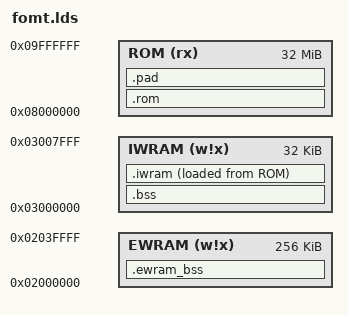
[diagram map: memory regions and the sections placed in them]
OUTPUT_ARCH(arm)

_M4aNumMusicPlayers = 5;
_M4aMaxLines = 0x50;

gMPlayJumpTableTemplate = 0x08139A88;
gScaleTable = 0x08139B18;
gFreqTable = 0x08139BCC;
gPcmSamplesPerVBlankTable = 0x08139BFC;
gCgbScaleTable = 0x08139C14;
gCgbFreqTable = 0x08139C98;
gNoiseTable = 0x08139CB0;
gCgb3Vol = 0x08139CEC;
gClockTable = 0x08139CFC;
gXcmdTable = 0x08139D30;

MEMORY
{
    EWRAM (w!x) : ORIGIN = 0x02000000, LENGTH = 256K
    IWRAM (w!x) : ORIGIN = 0x03000000, LENGTH = 32K
    ROM   (rx)  : ORIGIN = 0x08000000, LENGTH = 32M
}

SECTIONS
{
    .ewram_bss (NOLOAD) : ALIGN(4)
    {
        . = ALIGN(4); src/sound_data.o(.sbss);
        . = ALIGN(4); src/m4a.o(.gSoundInfo);
        . = ALIGN(4); src/m4a.o(.gMPlayJumpTable);
        . = ALIGN(4); src/m4a.o(.gCgbChans);
        . = ALIGN(4); src/m4a.o(.gMusicPlayerA);
        . = ALIGN(4); src/m4a.o(.gMusicPlayerB);
        . = ALIGN(4); src/m4a.o(.gMusicPlayerC);
        . = ALIGN(4); src/m4a.o(.gMusicPlayerE);
        . = ALIGN(4); src/m4a.o(.gMPlayMemAccArea);
        . = ALIGN(4); src/m4a.o(.gMusicPlayerD);
        __ewram_bss_end = .;
    } > EWRAM

    .bss (NOLOAD) : ALIGN(4)
    {
        . = ALIGN(4); src/m4a.o(.bss);
        . = ALIGN(4);
        . = 0x000400; gUnk_03000400 = .;
        . = 0x000402; gUnk_03000402 = .;
        . = 0x000404; gUnk_03000404 = .;
        . = 0x000408; gUnk_03000408 = .;
        . = 0x00040C; gUnk_0300040C = .;
        . = 0x000410; gUnk_03000410 = .;
        . = 0x000414; gUnk_03000414 = .;
        . = 0x000418; gUnk_03000418 = .;
        . = 0x00041C; gUnk_0300041C = .;
        . = 0x000420; gUnk_03000420 = .;
        . = 0x000430; gUnk_03000430 = .;
        . = 0x000450; gUnk_03000450 = .;
        . = 0x000490; /* end */
    } > IWRAM

    .rom : ALIGN(4)
    {
        src/crt0.o(.rom_header);
        asm/main.o(.text);
        asm/sram_proxy_1.o(.text);
        src/code_080003DC.o(.text);
        asm/sram_proxy_1.o(.text.tail080003E8);
        src/code_080004C4.o(.text);
        src/code_080004F4.o(.text);
        src/code_0800050C.o(.text);
        src/code_08000528.o(.text);
        src/code_08000540.o(.text);
        src/code_08000554.o(.text);
        src/code_08000568.o(.text);
        src/code_0800057C.o(.text);
        src/new.o(.text);
        src/pure_virtual.o(.text);
        src/code_0800063C.o(.text);
        src/code_08000640.o(.text);
        asm/sram_proxy_2_prefix.o(.text);
        src/code_080006A4.o(.text);
        src/code_080006E4.o(.text);
        src/code_08000714.o(.text);
        asm/sram_proxy_2.o(.text);
        src/scene.o(.text);
        asm/scene.o(.text);
        asm/intro_scene.o(.text);
        src/code_080036F8.o(.text);
        src/code_0800371C.o(.text);
        src/code_0800374C.o(.text);
        asm/new_game.o(.text);
        src/code_08004B58.o(.text);
        src/code_08004B94.o(.text);
        src/code_08004BDC.o(.text);
        src/code_08004C0C.o(.text);
        src/code_08004C48.o(.text);
        src/code_08004C54.o(.text);
        asm/code_08004C68.o(.text);
        src/code_08005254.o(.text);
        src/code_08005260.o(.text);
        asm/code_08004C68.o(.text.tail08005278);
        src/code_0800598C.o(.text);
        src/code_080059D0.o(.text);
        src/code_08005A00.o(.text);
        src/code_08005A3C.o(.text);
        asm/code_08005A58.o(.text);
        src/code_08007078.o(.text);
        src/code_080070A4.o(.text);
        src/code_080070D4.o(.text);
        src/code_08007110.o(.text);
        src/code_0800711C.o(.text);
        src/hardware.o(.text);
        src/code_080074C0.o(.text);
        asm/code_08007510.o(.text);
        src/code_0800770C.o(.text);
        asm/code_08007510.o(.text.tail08007714);
        src/code_08007D4C.o(.text);
        src/code_08007DB8.o(.text);
        src/code_08007E24.o(.text);
        src/code_08007E8C.o(.text);
        src/code_08007EA0.o(.text);
        src/code_08007EA8.o(.text);
        src/code_08007EC8.o(.text);
        asm/code_08007DB8.o(.text);
        src/code_0800835C.o(.text);
        asm/code_08007DB8.o(.text.tail08008364);
        src/code_080088B8.o(.text);
        src/code_080088C4.o(.text);
        src/code_080088CC.o(.text);
        src/code_080088D4.o(.text);
        src/code_080088DC.o(.text);
        src/code_08008910.o(.text);
        src/code_08008918.o(.text);
        src/code_08008920.o(.text);
        src/code_08008928.o(.text);
        src/code_08008940.o(.text);
        src/code_08008960.o(.text);
        src/code_08008980.o(.text);
        src/code_08008A68.o(.text);
        src/code_08008AE0.o(.text);
        src/code_08008AE8.o(.text);
        src/code_08008AF0.o(.text);
        src/code_08008AFC.o(.text);
        src/code_08008B0C.o(.text);
        src/code_08008B18.o(.text);
        src/code_08008B24.o(.text);
        src/code_08008B54.o(.text);
        src/code_08008B6C.o(.text);
        src/code_08008BB0.o(.text);
        src/code_08008BE0.o(.text);
        src/code_08008BEC.o(.text);
        src/code_08008BF8.o(.text);
        src/code_08008C08.o(.text);
        src/code_08008C28.o(.text);
        src/code_08008C38.o(.text);
        src/code_08008C54.o(.text);
        src/code_08008C70.o(.text);
        src/code_08008C8C.o(.text);
        src/code_08008CA8.o(.text);
        src/code_08008CC4.o(.text);
        src/code_08008CD0.o(.text);
        src/code_08008CDC.o(.text);
        asm/code_08008D10.o(.text);
        src/code_08008D2C.o(.text);
        src/code_08008D3C.o(.text);
        src/code_08008D5C.o(.text);
        src/code_08008D84.o(.text);
        src/code_08008D90.o(.text);
        src/code_08008D9C.o(.text);
        src/code_08008DA8.o(.text);
        src/code_08008DB8.o(.text);
        asm/code_08008DE8_prefix.o(.text);
        src/code_08008DE8.o(.text);
        src/code_08008DF4.o(.text);
        src/code_08008E04.o(.text);
        asm/code_08008E64_prefix.o(.text);
        src/code_08008E64.o(.text);
        src/code_08008EB8.o(.text);
        src/code_08008F0C.o(.text);
        asm/code_08008F60.o(.text);
        src/code_0800912C.o(.text);
        asm/code_08008F60.o(.text.tail08009140);
		src/code_08009158.o(.text.func_08009140);
        src/code_08009154.o(.text);
        asm/code_08008F60.o(.text.tail08009158);
		src/code_08009158.o(.text);
		asm/code_08008F60.o(.text.tail080091A4);
        src/code_080092FC.o(.text);
        asm/code_08008F60.o(.text.tail08009300);
        src/code_08009344.o(.text);
        asm/code_08008F60.o(.text.tail0800934C);
		src/code_simple_short.o(.text.func_080093A0);
		asm/code_08008F60.o(.text.tail080093AC);
        src/code_080094A4.o(.text);
        asm/code_08008F60.o(.text.tail080094AC);
        src/code_080094AC.o(.text);
        src/code_080094B8.o(.text);
        src/code_080094E0.o(.text);
        asm/code_0800956C_prefix.o(.text);
        src/code_0800956C.o(.text);
        src/code_0800959C.o(.text);
        src/code_080095C0.o(.text);
        src/code_080095FC.o(.text);
        src/code_08009638.o(.text);
        src/code_08009674.o(.text);
        asm/code_0800956C.o(.text);
        src/code_0800977C.o(.text);
        src/code_08009790.o(.text);
        asm/code_080097A4.o(.text);
        src/code_08009834.o(.text);
        src/code_08009864.o(.text);
        src/code_08009878.o(.text);
        src/code_080098AC.o(.text);
        asm/code_080098AC.o(.text);
        src/code_080098DC.o(.text);
        src/code_08009908.o(.text);
        src/code_08009940.o(.text);
        src/code_08009968.o(.text);
        src/code_08009984.o(.text);
        src/code_080099B0.o(.text);
        src/code_080099D4.o(.text);
        src/code_080099EC.o(.text);
        src/farm.o(.text);
        src/field.o(.text);
        src/shipping_bin.o(.text);
        src/tool_chest.o(.text);
        src/fridge.o(.text);
        src/shelf.o(.text);
        src/record_player.o(.text);
        src/code_0800BC58.o(.text);
        src/farm_house.o(.text);
        src/coop.o(.text);
        src/barn.o(.text);
        src/item.o(.text);
        src/code_0800E2E4.o(.text);
        src/farmer.o(.text);
        src/rucksack_item.o(.text);
        src/held_item.o(.text);
        src/rucksack.o(.text);
        asm/more_items.o(.text);
        src/code_0800FFD0.o(.text);
        src/code_0800FFD4.o(.text);
        src/code_0800FFD8.o(.text);
        src/code_0800FFE0.o(.text);
        src/code_0800FFF4.o(.text);
        src/code_08010014.o(.text);
        asm/more_items_tail.o(.text);
        asm/game_scene.o(.text);
        src/code_080100F0.o(.text);
        src/code_08010158.o(.text);
        asm/code_080101A0.o(.text);
        src/code_08010348.o(.text);
        asm/game_state.o(.text);
        src/code_08010E48.o(.text);
        asm/game_state.o(.text.tail08010E68);
        src/code_08010F04.o(.text);
        src/code_08010F0C.o(.text);
        src/code_08010F14.o(.text);
        src/game_state.o(.text);
        asm/code_08010F54.o(.text);
        src/code_08011458.o(.text);
		asm/code_08010F54.o(.text.tail08011464);
		src/code_simple_short.o(.text.func_08011510);
        src/code_0801151C.o(.text);
        asm/code_08010F54.o(.text.tail08011524);
        src/code_08011540.o(.text);
        asm/code_08010F54.o(.text.tail08011544);
        src/code_08011544.o(.text);
        asm/code_08010F54.o(.text.tail08011550);
        src/code_08011ED8.o(.text);
        src/code_08011FE8.o(.text);
        asm/code_08012028.o(.text);
        src/code_08012218.o(.text);
        asm/code_08012028.o(.text.tail0801221C);
		src/code_08012454.o(.text.func_08012454);
		asm/code_08012028.o(.text.tail08012464);
        src/code_080124C4.o(.text);
        asm/code_08012028.o(.text.tail080124D0);
		src/code_0801274C.o(.text.func_0801274C);
		asm/code_08012028.o(.text.tail08012760);
		src/code_0801274C.o(.text.func_0801278C);
		asm/code_08012028.o(.text.tail080127A0);
		src/code_0801274C.o(.text.func_0801284C);
		asm/code_08012028.o(.text.tail08012860);
		src/code_08012454.o(.text.func_08012ACC);
		asm/code_08012028.o(.text.tail08012ADC);
		src/code_08012454.o(.text.func_08012BAC);
		asm/code_08012028.o(.text.tail08012BBC);
		src/code_08012454.o(.text.func_080142F0);
		src/code_08012454.o(.text.func_08014304);
		asm/code_08012028.o(.text.tail08014318);
        src/code_0801468C.o(.text);
        asm/code_08012028.o(.text.tail08014694);
		src/code_08012454.o(.text.func_080167CC);
		asm/code_08012028.o(.text.tail080167DC);
		src/code_simple_short.o(.text.func_08016D9C);
		asm/code_08012028.o(.text.tail08016DB0);
        src/code_0801DD18.o(.text);
        src/code_0801DD24.o(.text);
        src/code_0801DD30.o(.text);
src/code_0801DD3C.o(.text);
        src/code_0801DD78.o(.text);
asm/code_0801DD78.o(.text);
        src/code_0801DDCC.o(.text);
        src/code_0801DDF8.o(.text);
        src/code_0801DE24.o(.text);
        src/code_0801DE30.o(.text);
        src/code_0801DE3C.o(.text);
        src/code_0801DE48.o(.text);
        asm/code_0801DE3C.o(.text);
		src/code_0801FAA8.o(.text);
		asm/code_0801DE3C.o(.text.tail0801FAC8);
        src/code_0801FD3C.o(.text);
        src/code_0801FD48.o(.text);
        src/code_0801FD60.o(.text);
        src/entity.o(.text);
        src/code_entity_08020018.o(.text);
        src/code_08020060.o(.text);
        asm/code_entities.o(.text);
        src/code_080202C4.o(.text);
        asm/code_entities.o(.text.tail080202CC);
		src/code_08020460.o(.text);
		asm/code_entities.o(.text.tail08020474);
        src/code_0802161C.o(.text);
		src/code_short_mappers.o(.text.func_08021620);
		asm/code_entities.o(.text.tail08021634);
        src/code_080222A8.o(.text);
        asm/code_08022320_prefix.o(.text);
        src/code_08022320.o(.text);
        src/code_08022334.o(.text);
        asm/code_08022320.o(.text);
		src/code_08037628.o(.text.func_080229A4);
		asm/code_08022320.o(.text.tail080229B8);
        src/code_08022B58.o(.text);
		src/code_short_mappers.o(.text.func_08022B5C);
		asm/code_08022320.o(.text.tail08022B70);
		src/code_08037628.o(.text.func_08023400);
		asm/code_08022320.o(.text.tail08023414);
		src/code_short_mappers.o(.text.func_080237F0);
		src/code_short_mappers.o(.text.func_08023804);
		asm/code_08022320.o(.text.tail08023820);
		src/code_08037628.o(.text.func_080240BC);
		asm/code_08022320.o(.text.tail080240D0);
		src/code_short_mappers.o(.text.func_080244C4);
		src/code_short_mappers.o(.text.func_080244D8);
		asm/code_08022320.o(.text.tail080244EC);
		src/code_08024BE8.o(.text);
		asm/code_08022320.o(.text.tail08024BFC);
		src/code_08024C54.o(.text);
		asm/code_08022320.o(.text.tail08024C74);
		src/code_08024C54.o(.text.func_08024C88);
        src/code_08024C98.o(.text);
        asm/code_08022320.o(.text.tail08024CA0);
		src/code_08025AFC.o(.text);
        asm/code_08022320.o(.text.tail08025B10);
        src/code_0802A7D8.o(.text);
        asm/code_08022320.o(.text.tail0802A7E0);
		src/code_0802C210.o(.text);
		asm/code_08022320.o(.text.tail0802C228);
        src/code_0802C2DC.o(.text);
        asm/code_08022320.o(.text.tail0802C2E0);
        src/entity_actor.o(.text);
        asm/code_entities_080320DC.o(.text);
        src/code_080324B8.o(.text);
        asm/code_entities_080320DC.o(.text.tail080324BC);
        src/code_08032A00.o(.text);
        asm/code_08032A30.o(.text);
		src/code_08033914.o(.text);
		asm/code_08032A30.o(.text.tail08033928);
        src/code_08033B7C.o(.text);
        asm/code_08032A30.o(.text.tail08033B84);
        src/npc_entity.o(.text);
        asm/code_entities_08034CEC.o(.text);
        src/code_08035B38.o(.text);
        src/code_08035B64.o(.text);
        src/code_08035B9C.o(.text);
        src/code_08035BC8.o(.text);
        asm/code_08035BC8.o(.text);
        src/code_08035CB8.o(.text);
        src/code_08035CD4.o(.text);
        src/code_08035D04.o(.text);
        src/code_08035D40.o(.text);
        src/code_08035D70.o(.text);
        src/code_08035DAC.o(.text);
        src/code_08035DD8.o(.text);
        src/code_08035E14.o(.text);
        src/code_08035E40.o(.text);
        src/code_08035E7C.o(.text);
        src/code_08035EAC.o(.text);
        src/code_08035EE4.o(.text);
        src/code_08035F10.o(.text);
        src/code_08035F48.o(.text);
        src/code_08035F74.o(.text);
        src/code_08035FB0.o(.text);
        src/code_08035FE0.o(.text);
        src/code_0803601C.o(.text);
        src/code_08036048.o(.text);
        asm/code_08036048.o(.text);
        src/code_08036138.o(.text);
        src/code_08036154.o(.text);
        src/code_08036184.o(.text);
        src/code_080361C0.o(.text);
        src/code_080361EC.o(.text);
        src/code_08036228.o(.text);
        src/code_08036258.o(.text);
        src/code_08036290.o(.text);
        src/code_080362C0.o(.text);
        src/code_080362FC.o(.text);
        src/code_08036328.o(.text);
        src/code_08036364.o(.text);
        src/code_08036390.o(.text);
        src/code_080363CC.o(.text);
        src/code_080363F8.o(.text);
        asm/code_080363F8.o(.text);
        src/code_080364E4.o(.text);
        src/code_08036500.o(.text);
        src/code_08036530.o(.text);
        src/code_08036564.o(.text);
        src/code_08036590.o(.text);
        asm/code_08036590.o(.text);
        src/code_08036680.o(.text);
        src/code_0803669C.o(.text);
        src/code_080366CC.o(.text);
        src/code_08036704.o(.text);
        src/code_08036730.o(.text);
        src/code_08036768.o(.text);
        src/code_080367AC.o(.text);
        src/code_080367C8.o(.text);
        src/code_080367F8.o(.text);
        src/code_08036834.o(.text);
        src/code_08036860.o(.text);
        src/code_08036898.o(.text);
        src/code_080368C4.o(.text);
        asm/code_080368C4.o(.text);
        src/code_080369C4.o(.text);
        src/code_080369E0.o(.text);
        src/code_08036A10.o(.text);
        src/code_08036A4C.o(.text);
        src/code_08036A78.o(.text);
        src/code_08036AB4.o(.text);
        src/code_08036B00.o(.text);
        src/code_08036B1C.o(.text);
        src/code_08036B4C.o(.text);
        src/code_08036B80.o(.text);
        asm/code_08036BB0.o(.text);
        src/code_08036C48.o(.text);
        src/code_08036C80.o(.text);
        src/code_08036CAC.o(.text);
        src/code_08036CDC.o(.text);
        src/code_08036D0C.o(.text);
        src/code_08036D3C.o(.text);
        src/code_08036D68.o(.text);
        src/code_08036D98.o(.text);
        src/code_08036DC4.o(.text);
        src/code_08036E00.o(.text);
        src/code_08036E2C.o(.text);
        asm/code_08036E2C.o(.text);
        src/code_08037244.o(.text);
        asm/code_08036E2C.o(.text.tail08037250);
        src/code_08037430.o(.text);
        asm/code_08036E2C.o(.text.tail08037434);
		src/code_0803745C.o(.text);
		asm/code_08036E2C.o(.text.tail08037470);
        src/code_0803753C.o(.text);
        asm/code_08037568.o(.text);
        src/code_08037618.o(.text);
		src/code_08037628.o(.text.func_08037628);
		asm/code_08037568.o(.text.tail0803763C);
        src/code_080376E4.o(.text);
        asm/code_08037714.o(.text);
        src/code_080377C4.o(.text);
		src/code_08037628.o(.text.func_080377D4);
		asm/code_08037714.o(.text.tail080377E8);
        src/code_0803788C.o(.text);
        src/code_080378B8.o(.text);
        src/code_080378EC.o(.text);
        src/code_080378FC.o(.text);
        asm/code_080378B8.o(.text);
        src/code_080379D8.o(.text);
        src/code_08037A04.o(.text);
        src/code_08037A38.o(.text);
        src/code_08037A48.o(.text);
        asm/code_08037A04.o(.text);
		src/code_08037CC4.o(.text);
		asm/code_08037A04.o(.text.tail08037CDC);
		src/code_allocator_wrappers.o(.text.func_08037CF0);
		asm/code_08037A04.o(.text.tail08037D08);
		src/code_allocator_wrappers.o(.text.func_08037E9C);
		asm/code_08037A04.o(.text.tail08037EB4);
        src/code_08037F74.o(.text);
        asm/code_08037A04.o(.text.tail08037F7C);
        src/code_08038108.o(.text);
        asm/code_08037A04.o(.text.tail08038110);
		src/code_08038320.o(.text);
		asm/code_08037A04.o(.text.tail08038334);
		src/code_allocator_wrappers.o(.text.func_08038334);
		asm/code_08037A04.o(.text.tail0803834C);
        src/code_0803836C.o(.text);
        asm/code_08037A04.o(.text.tail08038374);
		src/code_080387B8.o(.text.func_080387B8);
		src/code_080387B8.o(.text.func_080387C8);
		asm/code_08037A04.o(.text.tail080387D8);
		src/code_080387B8.o(.text.func_080387EC);
		src/code_080387B8.o(.text.func_080387FC);
		asm/code_08037A04.o(.text.tail0803880C);
		src/code_080387B8.o(.text.func_08038E90);
		asm/code_08037A04.o(.text.tail08038EA0);
        src/code_080390D0.o(.text);
        asm/code_08037A04.o(.text.tail080390DC);
        src/code_080391FC.o(.text);
        asm/code_08037A04.o(.text.tail08039204);
        src/code_0803930C.o(.text);
        asm/code_08037A04.o(.text.tail08039310);
		src/code_080396F4.o(.text);
		asm/code_08037A04.o(.text.tail08039708);
        src/code_08039A30.o(.text);
        src/code_08039A5C.o(.text);
        asm/code_08039A5C.o(.text);
        src/code_08039D4C.o(.text);
        asm/code_08039A5C.o(.text.tail08039D5C);
		src/code_08039D98.o(.text);
		asm/code_08039A5C.o(.text.tail08039DA8);
        src/code_0803A798.o(.text);
        src/code_0803A804.o(.text);

        asm/code_0803A8A4.o(.text);
        src/code_0803BDE4.o(.text);
        src/code_0803BDEC.o(.text);
        asm/code_0803A8A4.o(.text.tail0803BDEC);
        asm/code_0803A8A4.o(.text.tail0803BDFC);
        src/code_0803BE9C.o(.text);
        src/code_0803BEB0.o(.text);
        src/code_0803BEBC.o(.text);
        src/code_0803BEC8.o(.text);
        src/code_0803BED4.o(.text);
        src/code_0803BEE0.o(.text);
        src/code_0803BEEC.o(.text);
        src/code_0803BEF4.o(.text);
        src/code_0803BEFC.o(.text);
        src/code_0803BF08.o(.text);
        src/code_0803BF14.o(.text);
        src/code_0803BF78.o(.text);
        src/code_0803BFC8.o(.text);
        asm/code_0803BFC8_prefix.o(.text);
        src/code_0803C00C.o(.text);
        asm/code_0803D644_prefix.o(.text);
		src/code_0803C518.o(.text);
        src/code_0803C540.o(.text);
        src/code_0803C544.o(.text);
        asm/code_0803D644_prefix.o(.text.tail0803C54C);
        src/code_0803D644.o(.text);
        asm/code_0803BFC8.o(.text);
        src/script_engine.o(.text);
        asm/code_0803EE94.o(.text);
        src/code_0804E4AC.o(.text);
        src/code_0804E5AC.o(.text);
        src/code_0804E7A0.o(.text);
        asm/code_0804E7A0.o(.text);
        src/code_0804E8F0.o(.text);
        src/code_0804E958.o(.text);
        src/code_0804E9C8.o(.text);
        src/code_0804E9CC.o(.text);
        asm/code_0804E9C8.o(.text);
		src/code_0804EA80.o(.text.func_0804EA80);
		asm/code_0804E9C8.o(.text.tail0804EA94);
		src/code_0804EA80.o(.text.func_0804EDA0);
		asm/code_0804E9C8.o(.text.tail0804EDB4);
		src/code_0804EA80.o(.text.func_0804EE1C);
		asm/code_0804E9C8.o(.text.tail0804EE30);
		src/code_0804EA80.o(.text.func_0804EE88);
		asm/code_0804E9C8.o(.text.tail0804EE9C);
        src/code_0804F15C.o(.text);
		src/code_0804F160.o(.text);
        src/code_0804F174.o(.text);
        asm/code_0804E9C8.o(.text.tail0804F178);
		src/code_080503E4.o(.text);
		asm/code_0804E9C8.o(.text.tail08050424);
        src/code_080507D0.o(.text);
        asm/code_080507F8.o(.text);
        src/code_08050868.o(.text);
        asm/code_08050AD8.o(.text);
		src/code_08050B3C.o(.text.func_08050B3C);
		asm/code_08050AD8.o(.text.tail08050B50);
		src/code_08050B3C.o(.text.func_08050C18);
		asm/code_08050AD8.o(.text.tail08050C2C);
		src/code_08050C64.o(.text);
		asm/code_08050AD8.o(.text.tail08050C70);
        src/code_08050D0C.o(.text);
        src/code_08050D34.o(.text);
        src/code_08050D3C.o(.text);
        src/code_08050D5C.o(.text);
        src/code_08050D68.o(.text);
        src/code_08050D74.o(.text);
        src/code_08050D80.o(.text);
        src/code_08050D8C.o(.text);
        src/code_08050DA0.o(.text);
        src/code_08050DB4.o(.text);
        src/code_08050DC8.o(.text);
        src/code_08050DD8.o(.text);
        src/code_08050DE4.o(.text);
        src/code_08050DF0.o(.text);
        src/code_08050E0C.o(.text);
        src/code_08050E30.o(.text);
        src/code_08050E50.o(.text);
        src/code_08050E5C.o(.text);
        src/code_08050E68.o(.text);
        src/code_08050E74.o(.text);
        src/code_08050E80.o(.text);
        src/code_08050E8C.o(.text);
        src/code_08050E98.o(.text);
        src/code_08050EBC.o(.text);
        src/code_08050EE4.o(.text);
        asm/code_08050F4C.o(.text);
        src/code_08050F60.o(.text);
        src/code_08050F70.o(.text);
        src/code_08050F74.o(.text);
        asm/code_08050FA0.o(.text);
        src/code_080512B8.o(.text);
        src/code_080512C8.o(.text);
        src/code_080512D0.o(.text);
        src/code_080512D8.o(.text);
        asm/code_08051320.o(.text);
        src/code_0805218C.o(.text);
        src/code_080521BC.o(.text);
        src/code_080521FC.o(.text);
        asm/code_080521FC.o(.text);
		src/code_simple_short.o(.text.func_080522D8);
		src/code_simple_short.o(.text.func_080522E8);
		asm/code_080521FC.o(.text.tail080522F8);
        src/code_08057DD8.o(.text);
        src/code_08057E1C.o(.text);
        src/code_08057E5C.o(.text);
        asm/code_08057E5C.o(.text);
        src/code_0805CEB8.o(.text);
        src/code_0805CEFC.o(.text);
        src/code_0805CF3C.o(.text);
        asm/code_0805CF3C.o(.text);
        src/code_0805E624.o(.text);
        src/code_0805E658.o(.text);
        src/code_0805E698.o(.text);
        src/code_0805E6CC.o(.text);
        asm/code_0805E760.o(.text);
        src/code_0805E850.o(.text);
        src/code_0805E860.o(.text);
        asm/code_0805E860.o(.text);
        src/code_0805E8F0.o(.text);
        asm/code_0805E99C.o(.text);
        src/code_0805EC24.o(.text);
        asm/code_0805ED4C.o(.text);
        src/code_0805FCD0.o(.text);
        src/code_0805FD04.o(.text);
        src/code_0805FD44.o(.text);
        asm/code_0805FD44.o(.text);
		src/code_08063E58.o(.text);
		asm/code_0805FD44.o(.text.tail08063E64);
        src/code_08069E14.o(.text);
        src/code_08069E58.o(.text);
        src/code_08069E98.o(.text);
        src/code_08069EB4.o(.text);
        asm/code_08069F14.o(.text);
        src/code_0806D8C8.o(.text);
        src/code_0806D918.o(.text);
        src/code_0806D948.o(.text);
        src/code_0806D984.o(.text);
        asm/code_0806D948.o(.text);
        src/code_0806E9D8.o(.text);
        src/code_0806EA00.o(.text);
        src/code_0806EA30.o(.text);
        src/code_0806EA6C.o(.text);
        asm/code_0806EA78.o(.text);
        src/code_080709D8.o(.text);
        asm/code_08070A08.o(.text);
		src/code_vtable_tail_wrappers.o(.text.func_08070C88);
		asm/code_08070A08.o(.text.tail08070CA4);
		src/code_080713AC.o(.text.func_080713AC);
		asm/code_08070A08.o(.text.tail080713B8);
		src/code_080713AC.o(.text.func_080722D0);
		asm/code_08070A08.o(.text.tail080722DC);
		src/code_080713AC.o(.text.func_08075328);
		asm/code_08070A08.o(.text.tail08075334);
        src/code_080755EC.o(.text);
        src/code_0807561C.o(.text);
        src/code_0807565C.o(.text);
        src/code_08075678.o(.text);
        src/code_080756B0.o(.text);
        asm/code_080756D0.o(.text);
        src/code_08075DB8.o(.text);
        src/code_08075DD4.o(.text);
        src/code_08075DEC.o(.text);
        src/code_08075E00.o(.text);
        src/code_08075E24.o(.text);
        asm/code_08075E24.o(.text);
		src/code_08076BE0.o(.text);
		asm/code_08075E24.o(.text.tail08076BFC);
        src/code_08077C40.o(.text);
        asm/code_08077CE0.o(.text);
        src/code_0807B038.o(.text);
        asm/code_0807B0F0.o(.text);
        src/code_0807D070.o(.text);
        asm/code_0807D194_prefix.o(.text);
        src/code_0807D194.o(.text);
        asm/code_0807D1DC_prefix.o(.text);
        src/code_0807D1DC.o(.text);
        asm/code_0807D194.o(.text);
        src/code_0807DD38.o(.text);
        src/code_0807DD68.o(.text);
        src/code_0807DDA8.o(.text);
        src/code_0807DDC4.o(.text);
        asm/code_0807DDA8.o(.text);
        src/code_0807E438.o(.text);
        asm/code_0807E4B8.o(.text);
		src/code_vtable_wrappers.o(.text.func_0807E508);
		asm/code_0807E4B8.o(.text.tail0807E51C);
        src/code_0807EE14.o(.text);
        src/code_0807EE44.o(.text);
        src/code_0807EE84.o(.text);
        src/code_0807EEA0.o(.text);
        src/code_0807EED4.o(.text);
        src/code_0807EF00.o(.text);
        asm/code_0807EE84.o(.text);
        src/code_0807F580.o(.text);
        src/code_0807F5B0.o(.text);
        src/code_0807F5F0.o(.text);
        asm/code_0807F5F0_prefix.o(.text);
        src/code_0807F63C.o(.text);
        src/code_0807F670.o(.text);
        asm/code_0807F5F0.o(.text);
        src/code_0808045C.o(.text);
        src/code_0808048C.o(.text);
        src/code_080804CC.o(.text);
        asm/code_080804CC_prefix.o(.text);
        src/code_080804F8.o(.text);
        src/code_0808052C.o(.text);
        asm/code_080804CC.o(.text);
        src/code_08080D94.o(.text);
        src/code_08080DC4.o(.text);
        src/code_08080E04.o(.text);
        src/code_08080E20.o(.text);
        src/code_08080E54.o(.text);
        asm/code_08080E04.o(.text);
        src/code_08081A40.o(.text);
        src/code_08081A70.o(.text);
        src/code_08081AB0.o(.text);
        src/code_08081ACC.o(.text);
        src/code_08081B00.o(.text);
        src/code_08081B2C.o(.text);
        asm/code_08081AB0.o(.text);
        src/code_08082114.o(.text);
        src/code_08082144.o(.text);
        src/code_08082184.o(.text);
        asm/code_08082184.o(.text);
		src/code_vtable_wrappers.o(.text.func_08082250);
		asm/code_08082184.o(.text.tail08082264);
        src/code_08083AEC.o(.text);
        asm/code_08083B2C.o(.text);
		src/code_vtable_wrappers.o(.text.func_08083C50);
		asm/code_08083B2C.o(.text.tail08083C64);
        src/code_080854F4.o(.text);
        src/code_08085528.o(.text);
        src/code_08085568.o(.text);
        asm/code_08085568.o(.text);
		src/code_vtable_wrappers.o(.text.func_0808562C);
		asm/code_08085568.o(.text.tail08085640);
        src/code_08088168.o(.text);
        src/code_080881AC.o(.text);
        asm/code_080881EC.o(.text);
		src/code_vtable_wrappers.o(.text.func_08088304);
		asm/code_080881EC.o(.text.tail08088318);
        src/code_0808AB38.o(.text);
        src/code_0808AB68.o(.text);
        src/code_0808ABA8.o(.text);
        src/code_0808ABC4.o(.text);
        src/code_0808AC14.o(.text);
        asm/code_0808ABA8.o(.text);
        src/code_0808C56C.o(.text);
        src/code_0808C59C.o(.text);
        src/code_0808C5DC.o(.text);
        src/code_0808C5F8.o(.text);
        src/code_0808C650.o(.text);
        asm/code_0808C5DC.o(.text);
        src/code_0808ECD8.o(.text);
        src/code_0808ED08.o(.text);
        src/code_0808ED48.o(.text);
        src/code_0808ED64.o(.text);
        src/code_0808EDB8.o(.text);
        asm/code_0808ED48.o(.text);
        src/code_08090E54.o(.text);
        src/code_08090E84.o(.text);
        src/code_08090EC4.o(.text);
        asm/code_08090EC4.o(.text);
        src/code_080925C4.o(.text);
        asm/code_08092604.o(.text);
		src/code_vtable_wrappers.o(.text.func_08092690);
		asm/code_08092604.o(.text.tail080926A4);
        src/code_080931B0.o(.text);
        src/code_080931E0.o(.text);
        src/code_08093220.o(.text);
        asm/code_08093220.o(.text);
        src/code_08093A58.o(.text);
        src/code_08093A88.o(.text);
        src/code_08093AC8.o(.text);
        src/code_08093AD4.o(.text);
        asm/code_08093AC8.o(.text);
        src/code_08093C3C.o(.text);
        asm/code_08093AC8.o(.text.tail08093C40);
        src/code_08093F20.o(.text);
        asm/code_08093AC8.o(.text.tail08093F28);
        src/code_080943BC.o(.text);
        asm/code_08093AC8.o(.text.tail080943C4);
		src/code_080946A8.o(.text);
        src/code_080946BC.o(.text);
        asm/code_08093AC8.o(.text.tail080946C4);
        src/code_080948E0.o(.text);
        src/code_080948EC.o(.text);
        src/code_080948F8.o(.text);
        src/code_080948FC.o(.text);
        src/code_08094900.o(.text);
        src/code_08094904.o(.text);
        src/code_08094908.o(.text);
        src/code_0809490C.o(.text);
        src/code_08094910.o(.text);
        asm/code_080948FC_prefix.o(.text);
        src/code_08094940.o(.text);
        src/code_0809494C.o(.text);
        src/code_0809495C.o(.text);
        src/code_0809496C.o(.text);
        src/code_08094974.o(.text);
        src/code_08094994.o(.text);
        src/code_08094A00.o(.text);
        asm/code_080948FC.o(.text);
        src/code_0809A4D4.o(.text);
        src/code_0809A518.o(.text);
        src/code_0809A558.o(.text);
        asm/code_0809A558.o(.text);

        src/actor.o(.text);
        src/animal.o(.text);
        src/pet.o(.text);
        src/livestock.o(.text);
        src/barn_animal.o(.text);
        src/dog.o(.text);
        src/horse.o(.text);
        src/chicken.o(.text);
        src/cow.o(.text);
        src/sheep.o(.text);
        src/code_actor_0809BFE8.o(.text);
        src/code_0809C0A0.o(.text);
        src/code_0809C0AC.o(.text);
        src/code_0809C0BC.o(.text);
        src/code_0809C0C8.o(.text);
        asm/code_actor_0809BFE8.o(.text);
        src/code_0809C304.o(.text);
        src/code_0809C318.o(.text);
        src/code_0809C32C.o(.text);
        src/code_0809C38C.o(.text);
        src/code_0809C3BC.o(.text);
        src/code_0809C3E0.o(.text);
        src/code_0809C420.o(.text);
        src/code_0809C444.o(.text);
        src/code_0809C474.o(.text);
        src/code_0809C4B4.o(.text);
        src/code_0809C4E4.o(.text);
        asm/code_0809C32C.o(.text);
        src/code_0809C5EC.o(.text);
        asm/code_0809C32C.o(.text.tail0809C5F4);
        src/code_0809C5F4.o(.text);
        asm/code_0809C32C.o(.text.tail0809C600);
        src/code_0809C6AC.o(.text);
        asm/code_0809C32C.o(.text.tail0809C6BC);
        src/code_0809CE1C.o(.text);
        asm/code_0809C32C.o(.text.tail0809CE24);
        src/code_0809CE24.o(.text);
        asm/code_0809C32C.o(.text.tail0809CE30);
        src/code_0809CE7C.o(.text);
        asm/code_0809C32C.o(.text.tail0809CE8C);
        src/code_0809D8A0.o(.text);
		src/code_0809D8A4.o(.text);
		asm/code_0809C32C.o(.text.tail0809D8E8);
		src/code_0809E174.o(.text);
		asm/code_0809C32C.o(.text.tail0809E1B4);
        src/npc.o(.text);
        src/bachelorette.o(.text);
        src/harvest_sprite.o(.text);

        asm/code_809E804.o(.text);
        src/code_0809E988.o(.text);
        asm/code_809E804.o(.text.tail0809E994);
        src/code_0809EACC.o(.text);
        asm/code_809E804.o(.text.tail0809EAD0);
        src/code_0809EAD0.o(.text);
        asm/code_809E804.o(.text.tail0809EAD8);
        src/code_0809EAD8.o(.text);
        asm/code_809E804.o(.text.tail0809EAE0);
        src/code_0809EAE0.o(.text);
        asm/code_809E804.o(.text.tail0809EAEC);
        asm/code_809E804.o(.text.tail0809EAF8);
        src/code_0809EB68.o(.text);
        asm/code_809E804.o(.text.tail0809EB70);
        src/code_0809ECD8.o(.text);
        asm/code_809E804.o(.text.tail0809ECE0);
        src/code_080A039C.o(.text);
        asm/code_809E804.o(.text.tail080A03A4);
		src/code_080A0504.o(.text);
		asm/code_809E804.o(.text.tail080A0518);
        src/code_080A0B10.o(.text);
        asm/code_809E804.o(.text.tail080A0B18);
        src/code_080A1478.o(.text);
        src/code_080A1480.o(.text);
        asm/code_809E804.o(.text.tail080A1484);
        src/code_080A1A48.o(.text);
        asm/code_809E804.o(.text.tail080A1A4C);
        src/code_080A3744.o(.text);
        src/code_080A3774.o(.text);
        asm/code_080A3774.o(.text);
		src/code_080A5EA0.o(.text);
		asm/code_080A3774.o(.text.tail080A5EB8);
        src/code_080A601C.o(.text);
        asm/code_080A3774.o(.text.tail080A6024);
        src/code_080AAF9C.o(.text);
		asm/code_080AAFC8.o(.text);
		src/code_080AD938.o(.text);
		asm/code_080AAFC8.o(.text.tail080AD9DC);
        src/code_080ADB54.o(.text);
        src/code_080ADB78.o(.text);
        src/code_080ADB84.o(.text);
        src/code_080ADB9C.o(.text);
        src/code_080ADBA8.o(.text);
        src/code_080ADBB4.o(.text);
        src/code_080ADC00.o(.text);
        asm/code_080ADC84_prefix.o(.text);
        src/code_080ADC84.o(.text);
        asm/code_080ADB9C.o(.text);
        src/code_080ADD08.o(.text);
        src/code_080ADD20.o(.text);
        src/code_080ADD74.o(.text);
        src/code_080ADD78.o(.text);
        asm/code_080ADF40.o(.text);
        src/code_080AE4D8.o(.text);
        asm/code_080ADF40.o(.text.tail080AE4E4);
        src/code_080AE6C0.o(.text);
        asm/code_080ADF40.o(.text.tail080AE6CC);
		src/code_table_short.o(.text.func_080B3A10);
		asm/code_080ADF40.o(.text.tail080B3A28);
        src/code_080B3BE4.o(.text);
        src/code_080B3C0C.o(.text);
        asm/code_080B3C3C.o(.text);
		src/code_080B3C78.o(.text);
		asm/code_080B3C3C.o(.text.tail080B3C90);
		src/code_simple_short.o(.text.func_080B44E0);
		asm/code_080B3C3C.o(.text.tail080B44EC);
        src/code_080B45E4.o(.text);
        asm/code_080B3C3C.o(.text.tail080B45F0);
        src/code_080BA1F4.o(.text);
        asm/code_080B3C3C.o(.text.tail080BA204);
        src/code_080BC898.o(.text);
        src/code_080BC8C0.o(.text);
        src/code_080BC8F0.o(.text);
        asm/code_080BC8F0.o(.text);
		src/code_simple_short.o(.text.func_080BCCD4);
		asm/code_080BC8F0.o(.text.tail080BCCE0);
        src/code_080BCEBC.o(.text);
        asm/code_080BC8F0.o(.text.tail080BCEC8);
        src/code_080C0D1C.o(.text);
        src/code_080C0D44.o(.text);
        src/code_080C0D74.o(.text);
        src/code_080C0D80.o(.text);
        asm/code_080C0D74.o(.text);
        src/code_080C12B8.o(.text);
        asm/code_080C0D74.o(.text.tail080C12C4);
        src/code_080C14BC.o(.text);
        asm/code_080C0D74.o(.text.tail080C14C8);
		src/code_table_short.o(.text.func_080C7B64);
		asm/code_080C0D74.o(.text.tail080C7B7C);
        src/code_080C7EA8.o(.text);
        src/code_080C7ED0.o(.text);
        src/code_080C7F00.o(.text);
        src/code_080C7F0C.o(.text);
        asm/code_080C7F00.o(.text);
		src/code_simple_short.o(.text.func_080CAC70);
		asm/code_080C7F00.o(.text.tail080CAC7C);
        src/code_080CAD08.o(.text);
        src/code_080CAD10.o(.text);
        src/code_080CAD14.o(.text);
        asm/code_080CAD10.o(.text);
        src/code_080CADA0.o(.text);
        asm/code_080CAD10.o(.text.tail080CADA8);
        src/code_080CADA8.o(.text);
        asm/code_080CAD10.o(.text.tail080CADB4);
        src/code_080CB2FC.o(.text);
        asm/code_080CAD10.o(.text.tail080CB304);
		src/code_simple_short.o(.text.func_080CC134);
        src/code_080CC144.o(.text);
        asm/code_080CAD10.o(.text.tail080CC15C);
        src/code_080CC720.o(.text);
        asm/code_080CAD10.o(.text.tail080CC728);
        src/code_080CF050.o(.text);
        asm/code_080CAD10.o(.text.tail080CF05C);
		src/code_080D01E0.o(.text);
		asm/code_080CAD10.o(.text.tail080D01F8);
        src/code_080D02EC.o(.text);
        asm/code_080CAD10.o(.text.tail080D02F0);
		src/code_simple_short.o(.text.func_080D0444);
		asm/code_080CAD10.o(.text.tail080D0454);
		src/code_080D06A8.o(.text);
		asm/code_080CAD10.o(.text.tail080D06B4);
        src/code_080D06D0.o(.text);
        asm/code_080CAD10.o(.text.tail080D06DC);
        src/code_080D0C68.o(.text);
		src/code_080D0CD4.o(.text);
		asm/code_080D0CD4.o(.text);
		src/code_080D100C.o(.text);
		asm/code_080D0CD4.o(.text.tail080D102C);

        src/m4a_1.o(.text);
        src/m4a.o(.text);
        asm/code_lib_syscall.o(.text);
        src/code_080D3778.o(.text);
        asm/code_lib_sram.o(.text);
        *libgcc.a:_call_via_rX.o(.text);
        /* these need to be recompiled using -mthumb-interwork */
        /* *libc.a:memcmp.o(.text); */
        /* *libc.a:memcpy.o(.text); */
        /* *libc.a:memmove.o(.text); */
        /* *libc.a:memset.o(.text); */
        /* *libc.a:strcat.o(.text); */
        /* *libc.a:strcpy.o(.text); */
        /* *libc.a:strlen.o(.text); */
        asm/code_libc_string.o(.text);

        src/code_080D3BC0.o(.text);
        asm/code_linkonce.o(.text.code_080D3BC0);
		src/code_080D3C60.o(.text);
		asm/code_linkonce.o(.text.code_080D3C6C);
		src/code_080D3C6C.o(.text.func_080D3C6C);
		asm/code_linkonce.o(.text.code_080D3C78);
		src/code_080D3C6C.o(.text.func_080D4040);
		asm/code_linkonce.o(.text.code_080D404C);
        *(.gnu.linkonce.t.__as__6AnimalRC6Animal);
        asm/code_linkonce.o(.text.code_080D68C0);
		src/code_080D3C6C.o(.text.func_080D6D8C);
        src/code_080D6D98.o(.text);
        asm/code_080D6DB8.o(.text);
		src/code_080D6E98.o(.text);
		asm/code_080D6DB8.o(.text.tail080D6EAC);
		src/code_simple_short.o(.text.func_080D6F0C);
		asm/code_080D6DB8.o(.text.tail080D6F1C);
		src/code_080D780C.o(.text);
		asm/code_080D6DB8.o(.text.tail080D782C);
        src/code_080D7868.o(.text);
        asm/code_080D6DB8.o(.text.tail080D788C);
        src/code_080D7944.o(.text);
        asm/code_080D7990.o(.text);
        src/code_080D79CC.o(.text);
        asm/code_080D7AAC.o(.text);
        src/code_080D7AAC.o(.text);
        src/code_080D7AD4.o(.text);
        src/code_080D7B04.o(.text);
        src/code_080D7B2C.o(.text);
        *(.gnu.linkonce.t.__as__5SheepRC5Sheep);
        *(.gnu.linkonce.t.__as__3CowRC3Cow);
        *(.gnu.linkonce.t.__as__9LivestockRC9Livestock);
        *(.gnu.linkonce.t.push_back__t8FixedVec2Z12RucksackItemUl8G12RucksackItem);
        *(.gnu.linkonce.t.push_front__t8FixedVec2Z12RucksackItemUl8G12RucksackItem);
        *(.gnu.linkonce.t.push_back__t8FixedVec2Z9ToolStackUl8G9ToolStack);
        *(.gnu.linkonce.t.push_front__t8FixedVec2Z9ToolStackUl8G9ToolStack);
        asm/code_linkonce.o(.text.code_080D7CFC);
		src/code_080D7F60.o(.text.func_080D7F60);
		src/code_080D7F60.o(.text.func_080D7F74);
		src/code_080D7F60.o(.text.func_080D7F88);
		asm/code_linkonce.o(.text.code_080D7F9C);
		src/code_080D3C6C.o(.text.func_080DB314);
		asm/code_linkonce.o(.text.code_080DB320);
		src/code_080D3C6C.o(.text.func_080DC1C8);
		asm/code_linkonce.o(.text.code_080DC1D4);
		src/code_080D3C6C.o(.text.func_080DC288);
		asm/code_linkonce.o(.text.code_080DC294);
		src/code_080DCA2C.o(.text);
		asm/code_linkonce.o(.text.code_080DCB7C);
		src/code_080DCFCC.o(.text);
		asm/code_linkonce.o(.text.code_080DCFE0);
		src/code_080DD404.o(.text.func_080DD404);
		asm/code_linkonce.o(.text.code_080DD410);
		src/code_080DD404.o(.text.func_080DD4E4);
		asm/code_linkonce.o(.text.code_080DD4F0);
		src/code_080DD404.o(.text.func_080DD588);
		asm/code_linkonce.o(.text.code_080DD594);
		src/code_080DD404.o(.text.func_080DD788);
		asm/code_linkonce.o(.text.code_080DD794);
		src/code_080DD404.o(.text.func_080DD860);
		asm/code_linkonce.o(.text.code_080DD86C);
		src/code_080DD404.o(.text.func_080DD938);
		asm/code_linkonce.o(.text.code_080DD944);
		src/code_080DD404.o(.text.func_080DDC18);
		asm/code_linkonce.o(.text.code_080DDC24);
		src/code_080DD404.o(.text.func_080DDE68);
		asm/code_linkonce.o(.text.code_080DDE74);
		src/code_080DD404.o(.text.func_080DDF0C);
		asm/code_linkonce.o(.text.code_080DDF18);
		src/code_080DD404.o(.text.func_080DDFB0);
		asm/code_linkonce.o(.text.code_080DDFBC);
		src/code_080DE050.o(.text);
		asm/code_linkonce.o(.text.code_080DE05C);
		src/code_080DD404.o(.text.func_080DE128);
		asm/code_linkonce.o(.text.code_080DE134);
		src/code_080DE280.o(.text);
		asm/code_linkonce.o(.text.code_080DE298);
        src/code_080E09B0.o(.text);
        src/code_080E09BC.o(.text);
        src/code_080E09E4.o(.text);
        src/code_080E0A08.o(.text);
        src/code_080E0A7C.o(.text);
        src/code_080E0A88.o(.text);
        asm/code_080E09BC.o(.text);
		src/code_080E0D50.o(.text);
        src/code_080E0D64.o(.text);
        asm/code_080E09BC.o(.text.tail080E0D70);
        *(.gnu.linkonce.t.__lower_bound__H4ZPC12JumpTableEntZiZ28ScriptJumpTableSearchCompareZl_X01T0RCX11X21PX31_X01);
        asm/code_linkonce.o(.text.code_080E0EF0);
		src/code_080E0EF0.o(.text);
		asm/code_linkonce.o(.text.code_080E0EFC);
		src/code_080E1018.o(.text);
		asm/code_linkonce.o(.text.code_080E103C);
        src/code_080E10E0.o(.text);
        src/code_080E10EC.o(.text);
        src/code_080E10F0.o(.text);
        src/code_080E10F8.o(.text);
        src/code_080E1118.o(.text);
        src/code_080E111C.o(.text);
        src/code_080E1120.o(.text);
        src/code_080E1124.o(.text);
        src/code_080E1128.o(.text);
        src/code_080E1148.o(.text);
        src/code_080E118C.o(.text);
        asm/code_080E10F8.o(.text);
		src/code_080E1A48.o(.text.func_080E1A48);
		asm/code_080E10F8.o(.text.tail080E1A54);
		src/code_vtable_tail_wrappers.o(.text.func_080E1A54);
		asm/code_080E10F8.o(.text.tail080E1A70);
        src/code_080E1D8C.o(.text);
        asm/code_080E10F8.o(.text.tail080E1DD4);
        src/code_080E20F8.o(.text);
        asm/code_080E10F8.o(.text.tail080E211C);
		src/code_080E1A48.o(.text.func_080E35DC);
		asm/code_080E10F8.o(.text.tail080E35E8);
        src/code_080E3730.o(.text);
        asm/code_080E10F8.o(.text.tail080E3734);
        src/code_080E3858.o(.text);
        asm/code_080E10F8.o(.text.tail080E385C);
		src/code_080E1A48.o(.text.func_080E385C);
		src/code_080E1A48.o(.text.func_080E3868);
		asm/code_080E10F8.o(.text.tail080E3874);
        src/code_080E3910.o(.text);
        asm/code_080E10F8.o(.text.tail080E3914);
        asm/code_080E10F8.o(.text.tail080E3938);
        src/code_080E3A44.o(.text);
        asm/code_080E10F8.o(.text.tail080E3A5C);
		src/code_080E1A48.o(.text.func_080E3A5C);
		src/code_080E1A48.o(.text.func_080E3A6C);
		src/code_080E1A48.o(.text.func_080E3A80);
		src/code_080E1A48.o(.text.func_080E3A8C);
		asm/code_080E10F8.o(.text.tail080E3A9C);
        src/code_080E4190.o(.text);
        src/code_080E41B0.o(.text);
        src/code_080E41E8.o(.text);
        src/code_080E4210.o(.text);
        src/code_080E4238.o(.text);
        asm/code_080E41E8.o(.text);
        src/code_080E44B8.o(.text);
        src/code_080E44E4.o(.text);
        src/code_080E4510.o(.text);
        src/code_080E4544.o(.text);
        asm/code_080E4510.o(.text);
		src/code_080E5418.o(.text);
		asm/code_080E4510.o(.text.tail080E542C);
        src/code_080E59C0.o(.text);

        *(.gnu.linkonce.d.__vt_6AScene);
        *(.gnu.linkonce.d.__vt_13AUnk_0800080C);
        . = ALIGN(4); asm/vtables.o(.rodata);
        *(.gnu.linkonce.d.__vt_7AEntity);
        . = ALIGN(4); asm/vtables.o(.rodata.080E6284);
        *(.gnu.linkonce.d.__vt_13AScriptEngine);
        . = ALIGN(4); asm/vtables.o(.rodata.080E7824);

        . = ALIGN(4); asm/data/data_080E8610.o(.rodata);
        src/shipping_bin.o(.rodata);
        src/record_player.o(.rodata);
        . = ALIGN(4); src/item.o(.rodata);
        /* . = ALIGN(4); src/code_0800E2E4.o(.rodata); */
        . = ALIGN(4); asm/data/data_080F0348.o(.rodata);
        . = ALIGN(4); src/data_schedules.o(.rodata);
        . = ALIGN(4); asm/data/data_080F1A80.o(.rodata);
        . = ALIGN(4); src/script_engine.o(.rodata);
        . = ALIGN(4); asm/data/data_080F9EB8.o(.rodata);
        . = ALIGN(4); src/sound_data.o(.rodata.*);
        . = ALIGN(4); asm/data/data_0813B288.o(.rodata);
    } > ROM = 0xFF

    .iwram : ALIGN(4)
    {
        asm/code_iwram.o(.iwram);
    } > IWRAM AT> ROM = 0xFF

    __iwram_vma     = ADDR(.iwram);
    __iwram_vma_end = ADDR(.iwram) + SIZEOF(.iwram);
    __iwram_lma     = LOADADDR(.iwram);

    .pad : ALIGN(4)
    {
        LONG(0);
        . = 0x08800000 - 0x0875C240;
    } > ROM = 0xFF

    /* DWARF 2 sections */
    .debug_aranges  0 : { *(.debug_aranges) }
    .debug_pubnames 0 : { *(.debug_pubnames) }
    .debug_info     0 : { *(.debug_info) }
    .debug_abbrev   0 : { *(.debug_abbrev) }
    .debug_line     0 : { *(.debug_line) }
    .debug_frame    0 : { *(.debug_frame) }
    .debug_str      0 : { *(.debug_str) }
    .debug_loc      0 : { *(.debug_loc) }
    .debug_macinfo  0 : { *(.debug_macinfo) }

    /* Discard everything not specifically mentioned above. */
    /DISCARD/ :
    {
        *(*);
    }
}
